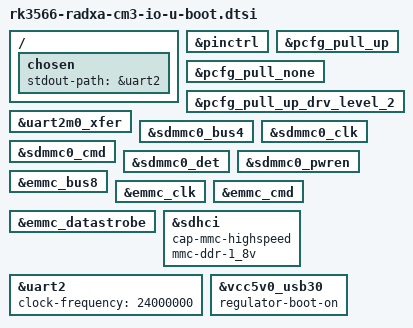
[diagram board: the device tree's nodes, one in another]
// SPDX-License-Identifier: GPL-2.0+
/*
 * (C) Copyright 2021 Rockchip Electronics Co., Ltd
 */

#include "rk356x-u-boot.dtsi"

/ {
	chosen {
		stdout-path = &uart2;
	};
};

&pinctrl {
	bootph-pre-ram;
};

&pcfg_pull_up {
	bootph-pre-ram;
};

&pcfg_pull_none {
	bootph-pre-ram;
};

&pcfg_pull_up_drv_level_2 {
	bootph-pre-ram;
};

&uart2m0_xfer {
	bootph-pre-ram;
};

&sdmmc0_bus4 {
	bootph-pre-ram;
};

&sdmmc0_clk {
	bootph-pre-ram;
};

&sdmmc0_cmd {
	bootph-pre-ram;
};

&sdmmc0_det {
	bootph-pre-ram;
};

&sdmmc0_pwren {
	bootph-pre-ram;
};

&emmc_bus8 {
	bootph-pre-ram;
};

&emmc_clk {
	bootph-pre-ram;
};

&emmc_cmd {
	bootph-pre-ram;
};

&emmc_datastrobe {
	bootph-pre-ram;
};

&sdhci {
	cap-mmc-highspeed;
	mmc-ddr-1_8v;
};

&uart2 {
	clock-frequency = <24000000>;
	bootph-all;
	status = "okay";
};

&vcc5v0_usb30 {
	regulator-boot-on;
};
